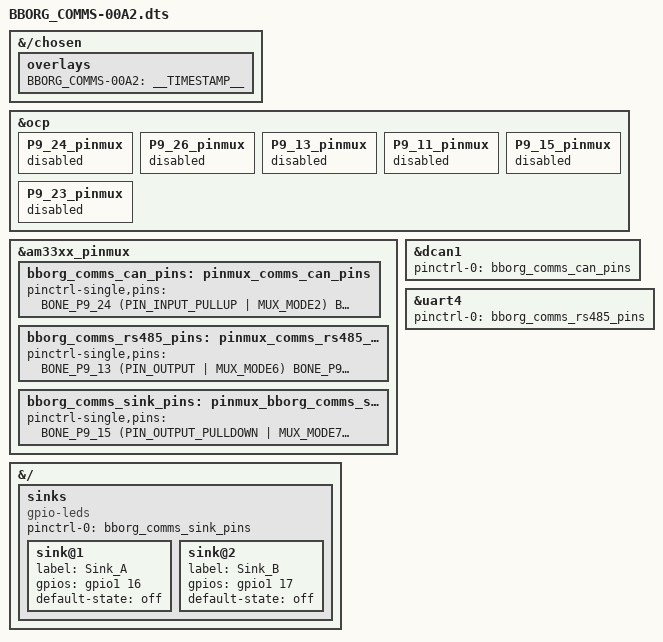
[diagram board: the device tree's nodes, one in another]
/*
 * Copyright (C) 2012,2019 Texas Instruments Incorporated - http://www.ti.com/
 * Copyright (C) 2015 Robert Nelson <robertcnelson@gmail.com>
 * Copyright (C) 2015 Sebastian Jegerås
 * Copyright (C) 2020, Deepak Khatri <deepaklorkhatri7@gmail.com>
 *
 * This program is free software; you can redistribute it and/or modify
 * it under the terms of the GNU General Public License version 2 as
 * published by the Free Software Foundation.
 */

/dts-v1/;
/plugin/;

#include <dt-bindings/board/am335x-bbw-bbb-base.h>
#include <dt-bindings/pinctrl/am33xx.h>
#include <dt-bindings/gpio/gpio.h>

/*
* Helper to show loaded overlays under: /proc/device-tree/chosen/overlays/
*/
&{/chosen} {
	overlays {
		BBORG_COMMS-00A2 = __TIMESTAMP__;
	};
};

/*
* Free up the pins used by the cape from the pinmux helpers.
*/
&ocp {
	P9_24_pinmux { status = "disabled"; };	/* P9_24: uart1_txd.d_can1_rx */
	P9_26_pinmux { status = "disabled"; };	/* P9_26: uart1_rxd.d_can1_tx */
	P9_13_pinmux { status = "disabled"; };	/* P9_13: gpmc_wpn.uart4_txd_mux2 */
	P9_11_pinmux { status = "disabled"; };	/* P9_11: gpmc_wait0.uart4_rxd_mux2 */
	P9_15_pinmux { status = "disabled"; };	/* P9_15: gpmc_a0.gpio1_16 */
	P9_23_pinmux { status = "disabled"; };	/* P9_23: gpmc_a1.gpio1_17 */
};

&am33xx_pinmux {
	bborg_comms_can_pins: pinmux_comms_can_pins {
		pinctrl-single,pins = <
			BONE_P9_24 (PIN_INPUT_PULLUP | MUX_MODE2)	/* P9_24: uart1_txd.d_can1_rx */
			BONE_P9_26 (PIN_OUTPUT_PULLUP | MUX_MODE2)	/* P9_26: uart1_rxd.d_can1_tx */
		>;
	};
	bborg_comms_rs485_pins: pinmux_comms_rs485_pins {
		pinctrl-single,pins = <
			BONE_P9_13 (PIN_OUTPUT | MUX_MODE6)	/* P9_13: gpmc_wpn.uart4_txd_mux2 */
			BONE_P9_11 (PIN_INPUT  | MUX_MODE6)	/* P9_11: gpmc_wait0.uart4_rxd_mux2 */
		>;
	};
	bborg_comms_sink_pins: pinmux_bborg_comms_sink_pins{
		pinctrl-single,pins = <
			BONE_P9_15 (PIN_OUTPUT_PULLDOWN | MUX_MODE7)	/* P9_15: gpmc_a0.gpio1_16 */
			BONE_P9_23 (PIN_OUTPUT_PULLDOWN | MUX_MODE7)	/* P9_23: gpmc_a1.gpio1_17 */
		>;
	};
};

&dcan1 {
	status = "okay";
	pinctrl-names = "default";
	pinctrl-0 = <&bborg_comms_can_pins>;
};
	
&uart4 {
	status = "okay";
	pinctrl-names = "default";
	pinctrl-0 = <&bborg_comms_rs485_pins>;
	//rs485-rts-delay = <0 0>;
	//rts-gpio = <&gpio3 19 1>; /*  GPIO_ACTIVE_HIGH>; */
	//rs485-rts-active-high;
	//linux,rs485-enabled-at-boot-time;
};

&{/} {

	sinks {
		pinctrl-names = "default";
		pinctrl-0 = <&bborg_comms_sink_pins>;
		compatible = "gpio-leds";

		sink@1 {
			label = "Sink_A";
			gpios = <&gpio1 16 GPIO_ACTIVE_HIGH>;
			default-state = "off";
		};

		sink@2 {
			label = "Sink_B";
			gpios = <&gpio1 17 GPIO_ACTIVE_HIGH>;
			default-state = "off";
		};
	};
};
